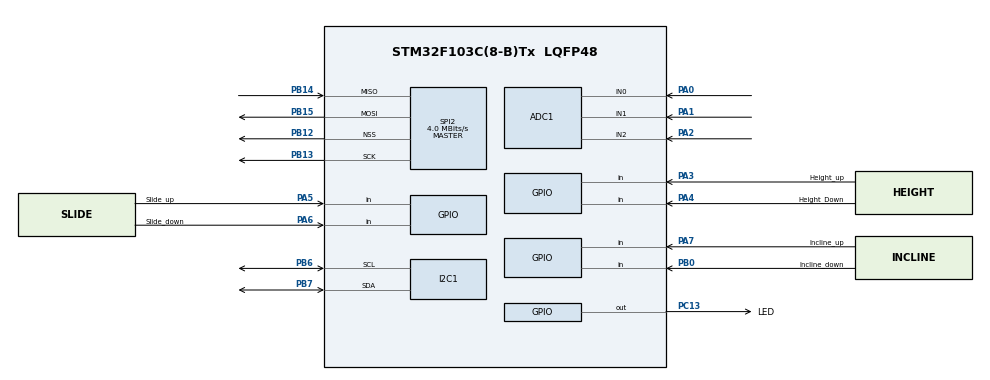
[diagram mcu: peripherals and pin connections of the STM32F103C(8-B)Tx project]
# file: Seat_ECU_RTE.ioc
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ADC1.Channel-0\#ChannelRegularConversion=ADC_CHANNEL_0
ADC1.NbrOfConversionFlag=1
ADC1.Rank-0\#ChannelRegularConversion=1
ADC1.SamplingTime-0\#ChannelRegularConversion=ADC_SAMPLETIME_1CYCLE_5
ADC1.master=1
FREERTOS.HEAP_NUMBER=3
FREERTOS.Tasks01=Task_Control,27,256,ControlTask,Default,NULL,Dynamic,NULL,NULL;Task_Input,26,128,InputTask,Default,NULL,Dynamic,NULL,NULL;Task_Comm,26,256,CommTask,Default,NULL,Dynamic,NULL,NULL;Task_Nvm,8,256,NvmTask,Default,NULL,Dynamic,NULL,NULL
FREERTOS.configUSE_NEWLIB_REENTRANT=1
Mcu.Family=STM32F1
Mcu.Name=STM32F103C(8-B)Tx
Mcu.Package=LQFP48
NVIC.PriorityGroup=NVIC_PRIORITYGROUP_4
NVIC.TIM1_UP_IRQn=true\:15\:0\:false\:false\:true\:false\:false\:true\:true
NVIC.TimeBase=TIM1_UP_IRQn
NVIC.TimeBaseIP=TIM1
PA0-WKUP.Signal=ADCx_IN0
PA1.Signal=ADCx_IN1
PA2.Signal=ADCx_IN2
PA3.GPIO_Label=Height_up
PA3.Signal=GPIO_Input
PA4.GPIO_Label=Height_Down
PA4.Signal=GPIO_Input
PA5.GPIO_Label=Slide_up
PA5.Signal=GPIO_Input
PA6.GPIO_Label=Slide_down
PA6.Signal=GPIO_Input
PA7.GPIO_Label=Incline_up
PA7.Signal=GPIO_Input
PB0.GPIO_Label=Incline_down
PB0.Signal=GPIO_Input
PB12.Mode=NSS_Signal_Hard_Output
PB12.Signal=SPI2_NSS
PB13.Mode=Full_Duplex_Master
PB13.Signal=SPI2_SCK
PB14.Mode=Full_Duplex_Master
PB14.Signal=SPI2_MISO
PB15.Mode=Full_Duplex_Master
PB15.Signal=SPI2_MOSI
PB6.Mode=I2C
PB6.Signal=I2C1_SCL
PB7.Mode=I2C
PB7.Signal=I2C1_SDA
PC13-TAMPER-RTC.GPIO_Label=LED
PC13-TAMPER-RTC.Signal=GPIO_Output
PC14-OSC32_IN.Mode=LSE-External-Oscillator
PC14-OSC32_IN.Signal=RCC_OSC32_IN
PC15-OSC32_OUT.Mode=LSE-External-Oscillator
PC15-OSC32_OUT.Signal=RCC_OSC32_OUT
PD0-OSC_IN.Mode=HSE-External-Oscillator
PD0-OSC_IN.Signal=RCC_OSC_IN
PD1-OSC_OUT.Mode=HSE-External-Oscillator
PD1-OSC_OUT.Signal=RCC_OSC_OUT
ProjectManager.HeapSize=0x200
ProjectManager.StackSize=0x400
ProjectManager.TargetToolchain=STM32CubeIDE
RCC.APB1Freq_Value=8000000
RCC.APB2Freq_Value=8000000
SH.ADCx_IN0.0=ADC1_IN0,IN0
SH.ADCx_IN1.0=ADC1_IN1,IN1
SH.ADCx_IN2.0=ADC1_IN2,IN2
SPI2.CalculateBaudRate=4.0 MBits/s
SPI2.Direction=SPI_DIRECTION_2LINES
SPI2.Mode=SPI_MODE_MASTER
SPI2.VirtualNSS=VM_NSSHARD
SPI2.VirtualType=VM_MASTER
VP_FREERTOS_VS_CMSIS_V2.Mode=CMSIS_V2
VP_SYS_VS_ND.Mode=No_Debug
VP_SYS_VS_tim1.Mode=TIM1
board=custom

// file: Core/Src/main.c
/* USER CODE BEGIN Header */
/**
  ******************************************************************************
  * @file           : main.c
  * @brief          : Main program body
  ******************************************************************************
  * @attention
  *
  * Copyright (c) 2025 STMicroelectronics.
  * All rights reserved.
  *
  * This software is licensed under terms that can be found in the LICENSE file
  * in the root directory of this software component.
  * If no LICENSE file comes with this software, it is provided AS-IS.
  *
  ******************************************************************************
  */
/* USER CODE END Header */
#include "main.h"
#include "cmsis_os.h"

/* USER CODE BEGIN Includes */
#include "../SeatController.h"
/* USER CODE END Includes */

ADC_HandleTypeDef hadc1;

I2C_HandleTypeDef hi2c1;

SPI_HandleTypeDef hspi2;

/* Definitions for Task_Control */
osThreadId_t Task_ControlHandle;
const osThreadAttr_t Task_Control_attributes = {
  .name = "Task_Control",
  .stack_size = 256 * 4,
  .priority = (osPriority_t) osPriorityNormal3,
};
/* Definitions for Task_Input */
osThreadId_t Task_InputHandle;
const osThreadAttr_t Task_Input_attributes = {
  .name = "Task_Input",
  .stack_size = 128 * 4,
  .priority = (osPriority_t) osPriorityNormal2,
};
/* Definitions for Task_Comm */
osThreadId_t Task_CommHandle;
const osThreadAttr_t Task_Comm_attributes = {
  .name = "Task_Comm",
  .stack_size = 256 * 4,
  .priority = (osPriority_t) osPriorityNormal2,
};
/* Definitions for Task_Nvm */
osThreadId_t Task_NvmHandle;
const osThreadAttr_t Task_Nvm_attributes = {
  .name = "Task_Nvm",
  .stack_size = 256 * 4,
  .priority = (osPriority_t) osPriorityLow,
};

void SystemClock_Config(void);
static void MX_GPIO_Init(void);
static void MX_ADC1_Init(void);
static void MX_I2C1_Init(void);
static void MX_SPI2_Init(void);
void ControlTask(void *argument);
void InputTask(void *argument);
void CommTask(void *argument);
void NvmTask(void *argument);

int main(void)
{

  /* MCU Configuration--------------------------------------------------------*/

  /* Reset of all peripherals, Initializes the Flash interface and the Systick. */
  HAL_Init();

  /* Configure the system clock */
  SystemClock_Config();

  /* Initialize all configured peripherals */
  MX_GPIO_Init();
  MX_ADC1_Init();
  MX_I2C1_Init();
  MX_SPI2_Init();

  /* Init scheduler */
  osKernelInitialize();

  /* Create the thread(s) */
  /* creation of Task_Control */
  Task_ControlHandle = osThreadNew(ControlTask, NULL, &Task_Control_attributes);

  /* creation of Task_Input */
  Task_InputHandle = osThreadNew(InputTask, NULL, &Task_Input_attributes);

  /* creation of Task_Comm */
  Task_CommHandle = osThreadNew(CommTask, NULL, &Task_Comm_attributes);

  /* creation of Task_Nvm */
  Task_NvmHandle = osThreadNew(NvmTask, NULL, &Task_Nvm_attributes);

  /* Start scheduler */
  osKernelStart();

  /* We should never get here as control is now taken by the scheduler */

  /* Infinite loop */
  while (1)
  {

  }
}

void SystemClock_Config(void)
{
  RCC_OscInitTypeDef RCC_OscInitStruct = {0};
  RCC_ClkInitTypeDef RCC_ClkInitStruct = {0};
  RCC_PeriphCLKInitTypeDef PeriphClkInit = {0};

  /** Initializes the RCC Oscillators according to the specified parameters
  * in the RCC_OscInitTypeDef structure.
  */
  RCC_OscInitStruct.OscillatorType = RCC_OSCILLATORTYPE_HSI;
  RCC_OscInitStruct.HSIState = RCC_HSI_ON;
  RCC_OscInitStruct.HSICalibrationValue = RCC_HSICALIBRATION_DEFAULT;
  RCC_OscInitStruct.PLL.PLLState = RCC_PLL_NONE;
  if (HAL_RCC_OscConfig(&RCC_OscInitStruct) != HAL_OK)
  {
    Error_Handler();
  }

  /** Initializes the CPU, AHB and APB buses clocks
  */
  RCC_ClkInitStruct.ClockType = RCC_CLOCKTYPE_HCLK|RCC_CLOCKTYPE_SYSCLK
                              |RCC_CLOCKTYPE_PCLK1|RCC_CLOCKTYPE_PCLK2;
  RCC_ClkInitStruct.SYSCLKSource = RCC_SYSCLKSOURCE_HSI;
  RCC_ClkInitStruct.AHBCLKDivider = RCC_SYSCLK_DIV1;
  RCC_ClkInitStruct.APB1CLKDivider = RCC_HCLK_DIV1;
  RCC_ClkInitStruct.APB2CLKDivider = RCC_HCLK_DIV1;

  if (HAL_RCC_ClockConfig(&RCC_ClkInitStruct, FLASH_LATENCY_0) != HAL_OK)
  {
    Error_Handler();
  }
  PeriphClkInit.PeriphClockSelection = RCC_PERIPHCLK_ADC;
  PeriphClkInit.AdcClockSelection = RCC_ADCPCLK2_DIV2;
  if (HAL_RCCEx_PeriphCLKConfig(&PeriphClkInit) != HAL_OK)
  {
    Error_Handler();
  }
}

static void MX_ADC1_Init(void)
{

  ADC_ChannelConfTypeDef sConfig = {0};

  /** Common config
  */
  hadc1.Instance = ADC1;
  hadc1.Init.ScanConvMode = ADC_SCAN_DISABLE;
  hadc1.Init.ContinuousConvMode = DISABLE;
  hadc1.Init.DiscontinuousConvMode = DISABLE;
  hadc1.Init.ExternalTrigConv = ADC_SOFTWARE_START;
  hadc1.Init.DataAlign = ADC_DATAALIGN_RIGHT;
  hadc1.Init.NbrOfConversion = 1;
  if (HAL_ADC_Init(&hadc1) != HAL_OK)
  {
    Error_Handler();
  }

  /** Configure Regular Channel
  */
  sConfig.Channel = ADC_CHANNEL_0;
  sConfig.Rank = ADC_REGULAR_RANK_1;
  sConfig.SamplingTime = ADC_SAMPLETIME_1CYCLE_5;
  if (HAL_ADC_ConfigChannel(&hadc1, &sConfig) != HAL_OK)
  {
    Error_Handler();
  }

}

static void MX_I2C1_Init(void)
{

  hi2c1.Instance = I2C1;
  hi2c1.Init.ClockSpeed = 100000;
  hi2c1.Init.DutyCycle = I2C_DUTYCYCLE_2;
  hi2c1.Init.OwnAddress1 = 0;
  hi2c1.Init.AddressingMode = I2C_ADDRESSINGMODE_7BIT;
  hi2c1.Init.DualAddressMode = I2C_DUALADDRESS_DISABLE;
  hi2c1.Init.OwnAddress2 = 0;
  hi2c1.Init.GeneralCallMode = I2C_GENERALCALL_DISABLE;
  hi2c1.Init.NoStretchMode = I2C_NOSTRETCH_DISABLE;
  if (HAL_I2C_Init(&hi2c1) != HAL_OK)
  {
    Error_Handler();
  }

}

static void MX_SPI2_Init(void)
{

  /* SPI2 parameter configuration*/
  hspi2.Instance = SPI2;
  hspi2.Init.Mode = SPI_MODE_MASTER;
  hspi2.Init.Direction = SPI_DIRECTION_2LINES;
  hspi2.Init.DataSize = SPI_DATASIZE_8BIT;
  hspi2.Init.CLKPolarity = SPI_POLARITY_LOW;
  hspi2.Init.CLKPhase = SPI_PHASE_1EDGE;
  hspi2.Init.NSS = SPI_NSS_HARD_OUTPUT;
  hspi2.Init.BaudRatePrescaler = SPI_BAUDRATEPRESCALER_2;
  hspi2.Init.FirstBit = SPI_FIRSTBIT_MSB;
  hspi2.Init.TIMode = SPI_TIMODE_DISABLE;
  hspi2.Init.CRCCalculation = SPI_CRCCALCULATION_DISABLE;
  hspi2.Init.CRCPolynomial = 10;
  if (HAL_SPI_Init(&hspi2) != HAL_OK)
  {
    Error_Handler();
  }

}

static void MX_GPIO_Init(void)
{
  GPIO_InitTypeDef GPIO_InitStruct = {0};

  /* GPIO Ports Clock Enable */
  __HAL_RCC_GPIOC_CLK_ENABLE();
  __HAL_RCC_GPIOD_CLK_ENABLE();
  __HAL_RCC_GPIOA_CLK_ENABLE();
  __HAL_RCC_GPIOB_CLK_ENABLE();

  /*Configure GPIO pin Output Level */
  HAL_GPIO_WritePin(LED_GPIO_Port, LED_Pin, GPIO_PIN_RESET);

  /*Configure GPIO pin : LED_Pin */
  GPIO_InitStruct.Pin = LED_Pin;
  GPIO_InitStruct.Mode = GPIO_MODE_OUTPUT_PP;
  GPIO_InitStruct.Pull = GPIO_NOPULL;
  GPIO_InitStruct.Speed = GPIO_SPEED_FREQ_LOW;
  HAL_GPIO_Init(LED_GPIO_Port, &GPIO_InitStruct);

  /*Configure GPIO pins : Height_up_Pin Height_Down_Pin Slide_up_Pin Slide_down_Pin
                           Incline_up_Pin */
  GPIO_InitStruct.Pin = Height_up_Pin|Height_Down_Pin|Slide_up_Pin|Slide_down_Pin
                          |Incline_up_Pin;
  GPIO_InitStruct.Mode = GPIO_MODE_INPUT;
  GPIO_InitStruct.Pull = GPIO_NOPULL;
  HAL_GPIO_Init(GPIOA, &GPIO_InitStruct);

  /*Configure GPIO pin : Incline_down_Pin */
  GPIO_InitStruct.Pin = Incline_down_Pin;
  GPIO_InitStruct.Mode = GPIO_MODE_INPUT;
  GPIO_InitStruct.Pull = GPIO_NOPULL;
  HAL_GPIO_Init(Incline_down_GPIO_Port, &GPIO_InitStruct);

}

void ControlTask(void *argument)
{
  /* USER CODE BEGIN 5 */
  uint8_t testData = 0xAB;
  /* Infinite loop */
  for(;;)
  {
	HAL_I2C_Master_Transmit(&hi2c1,
							I2C_SLAVE_ADDR,
							&testData,
							sizeof(testData),
							HAL_MAX_DELAY);
    osDelay(100);
  }
  /* USER CODE END 5 */
}

void InputTask(void *argument)
{
  for(;;)
  {
    osDelay(1);
  }
}

void CommTask(void *argument)
{
  for(;;)
  {
    osDelay(1);
  }
}

void NvmTask(void *argument)
{
  for(;;)
  {
    osDelay(1);
  }
}

void HAL_TIM_PeriodElapsedCallback(TIM_HandleTypeDef *htim)
{
  if (htim->Instance == TIM1)
  {
    HAL_IncTick();
  }
}

void Error_Handler(void)
{
  __disable_irq();
  while (1)
  {
  }
}
